# M261_v1 register map
File version: 1.0
Registers are 32-bit, read-write, reset 0x0 unless marked. A register's access mark holds for its fields unless they carry their own. Offsets are from the block's base; [hi:lo] are bit positions; {n}, {i} and the like mark numbered series; 'fields as' and 'values as' point back to an identical list.

## EADC — EADC Register Map
Base 0x40043000
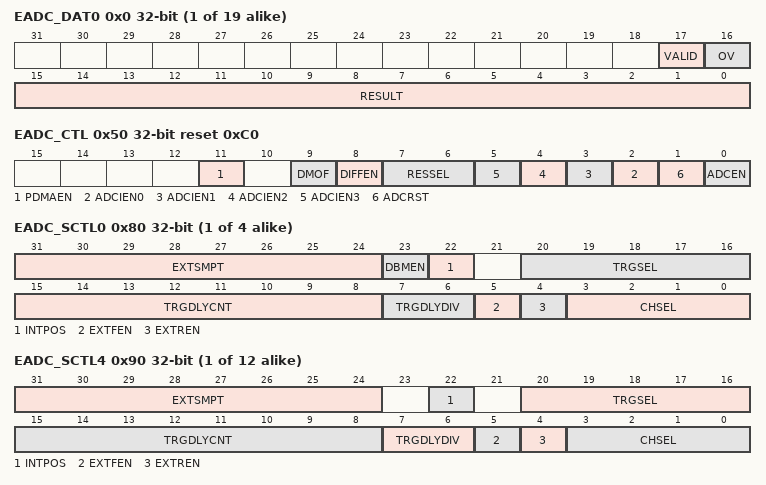
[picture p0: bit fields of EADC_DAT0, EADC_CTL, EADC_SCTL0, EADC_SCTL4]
{0x0+4i} EADC_DAT{i} ro (i=0..18) — ADC Data Register {i} for Sample Module {i}
  [17] VALID — Valid Flag. This bit is set to 1 when corresponding sample module channel analog input conversion is completed and cleared by hardware after EADC_DAT register is read.
    0=Data in RESULT[11:0] bits is not valid; 1=Data in RESULT[11:0] bits is valid
  [16] OV — Overrun Flag. If converted data in RESULT[11:0] has not been read before new conversion result is loaded to this register, OV is set to 1. Note: It is cleared by hardware after EADC_DAT register is read.
    0=Data in RESULT[11:0] is recent conversion result; 1=Data in RESULT[11:0] is overwrite
  [15:0] RESULT — ADC Conversion Result. This field contains 12 bits conversion result. When DMOF (EADC_CTL[9]) is set to 0, 12-bit ADC conversion result with unsigned format will be filled in RESULT[11:0] and zero will be filled in RESULT[15:12]. When DMOF (EADC_CTL[9]) set to 1, 12-bit ADC conversion result with 2'complement format will be filled in RESULT[11:0] and signed bits to will be filled in RESULT[15:12].
0x4C EADC_CURDAT ro — ADC PDMA Current Transfer Data Register
  [17:0] CURDAT — ADC PDMA Current Transfer Data (Read Only)
0x50 EADC_CTL reset 0xC0 — ADC Control Register
  [11] PDMAEN — PDMA Transfer Enable Bit. When ADC conversion is completed, the converted data is loaded into EADC_DATn (n: 0 ~ 18) register, user can enable this bit to generate a PDMA data transfer request.
    0=PDMA data transfer Disabled; 1=PDMA data transfer Enabled
  [9] DMOF — ADC Differential Input Mode Output Format
    0=ADC conversion result will be filled in RESULT (EADC_DATn[15:0], where n= 0 ~18) with unsigned format; 1=ADC conversion result will be filled in RESULT (EADC_DATn[15:0], where n= 0 ~18) with 2'complement format
  [8] DIFFEN — Differential Analog Input Mode Enable Bit
    0=Single-end analog input mode; 1=Differential analog input mode
  [7:6] RESSEL — Resolution Selection
    0=6-bit ADC result will be put at RESULT (EADC_DATn[5:0]); 1=8-bit ADC result will be put at RESULT (EADC_DATn[7:0]); 2=10-bit ADC result will be put at RESULT (EADC_DATn[9:0]); 3=12-bit ADC result will be put at RESULT (EADC_DATn[11:0])
  [n+2] ADCIEN{n} (n=0..3) — Specific Sample Module ADC ADINT{n} Interrupt Enable Bit. The ADC converter generates a conversion end ADIF{n} (EADC_STATUS2[{n}]) upon the end of specific sample module ADC conversion. If ADCIEN{n} bit is set then conversion end interrupt request ADINT{n} is generated.
    0=Specific sample module ADC ADINT{n} interrupt function Disabled; 1=Specific sample module ADC ADINT{n} interrupt function Enabled
  [1] ADCRST — ADC Converter Control Circuits Reset. Note: ADCRST bit remains 1 during ADC reset, when ADC reset end, the ADCRST bit is automatically cleared to 0.
    0=No effect; 1=Cause ADC control circuits reset to initial state, but not change the ADC registers value
  [0] ADCEN — ADC Converter Enable Bit. Note: Before starting ADC conversion function, this bit should be set to 1. Clear it to 0 to disable ADC converter analog circuit power consumption.
    0=Disabled EADC; 1=Enabled EADC
0x54 EADC_SWTRG wo — ADC Sample Module Software Start Register
  [18:0] SWTRG — ADC Sample Module 0~18 Software Force to Start ADC Conversion. Note: After writing this register to start ADC conversion, the EADC_PENDSTS register will show which sample module will conversion. If user want to disable the conversion of the sample module, user can write EADC_PENDSTS register to clear it.
    0=No effect; 1=Cause an ADC conversion when the priority is given to sample module
0x58 EADC_PENDSTS — ADC Start of Conversion Pending Flag Register
  [18:0] STPF — ADC Sample Module 0~18 Start of Conversion Pending Flag. Read Operation:
    0=There is no pending conversion for sample module; 1=Sample module ADC start of conversion is pending. Cear pending flag cancel the conversion for sample module
0x5C EADC_OVSTS — ADC Sample Module Start of Conversion Overrun Flag Register
  [18:0] SPOVF — ADC SAMPLE0~18 Overrun Flag. Note: This bit is cleared by writing 1 to it.
    0=No sample module event overrun; 1=Indicates a new sample module event is generated while an old one event is pending
{0x80+4i} EADC_SCTL{i} (i=0..3) — ADC Sample Module {i} Control Register
  [31:24] EXTSMPT — ADC Sampling Time Extend. When ADC converting at high conversion rate, the sampling time of analog input voltage may not enough if input channel loading is heavy, user can extend ADC sampling time after trigger source is coming to get enough sampling time. The range of start delay time is from 0~255 ADC clock.
  [23] DBMEN — Double Buffer Mode Enable Bit
    0=Sample has one sample result register (default); 1=Sample has two sample result registers
  [22] INTPOS — Interrupt Flag Position Select
    0=Set ADIFn (EADC_STATUS2[n], n=0~3) at ADC end of conversion; 1=Set ADIFn (EADC_STATUS2[n], n=0~3) at ADC start of conversion
  [20:16] TRGSEL — ADC Sample Module Start of Conversion Trigger Source Selection
  [15:8] TRGDLYCNT — ADC Sample Module Start of Conversion Trigger Delay Time
  [7:6] TRGDLYDIV — ADC Sample Module Start of Conversion Trigger Delay Clock Divider Selection. Trigger delay clock frequency:
    0=ADC_CLK/1; 1=ADC_CLK/2; 2=ADC_CLK/4; 3=ADC_CLK/16
  [5] EXTFEN — ADC External Trigger Falling Edge Enable Bit
    0=Falling edge Disabled when ADC selects EADC0_ST as trigger source; 1=Falling edge Enabled when ADC selects EADC0_ST as trigger source
  [4] EXTREN — ADC External Trigger Rising Edge Enable Bit
    0=Rising edge Disabled when ADC selects EADC0_ST as trigger source; 1=Rising edge Enabled when ADC selects EADC0_ST as trigger source
  [3:0] CHSEL — ADC Sample Module Channel Selection
{0x80+4i} EADC_SCTL{i} (i=4..15) — ADC Sample Module {i} Control Register
  [31:24] EXTSMPT — ADC Sampling Time Extend. When ADC converting at high conversion rate, the sampling time of analog input voltage may not enough if input channel loading is heavy, SW can extend ADC sampling time after trigger source is coming to get enough sampling time. The range of start delay time is from 0~255 ADC clock.
  [22] INTPOS — Interrupt Flag Position Select
    values as EADC_SCTL0.INTPOS
  [20:16] TRGSEL — ADC Sample Module Start of Conversion Trigger Source Selection
  [15:8] TRGDLYCNT — ADC Sample Module Start of Conversion Trigger Delay Time
  [7:6] TRGDLYDIV — ADC Sample Module Start of Conversion Trigger Delay Clock Divider Selection. Trigger delay clock frequency:
    0=ADC_CLK/1; 1=ADC_CLK/2; 2=ADC_CLK/4; 3=ADC_CLK/16
  [5] EXTFEN — ADC External Trigger Falling Edge Enable Bit
    values as EADC_SCTL0.EXTFEN
  [4] EXTREN — ADC External Trigger Rising Edge Enable Bit
    values as EADC_SCTL0.EXTREN
  [3:0] CHSEL — ADC Sample Module Channel Selection
{0x80+4i} EADC_SCTL{i} (i=16..18) — ADC Sample Module {i} Control Register
  [31:24] EXTSMPT — ADC Sampling Time Extend. When ADC converting at high conversion rate, the sampling time of analog input voltage may not enough if input channel loading is heavy, SW can extend ADC sampling time after trigger source is coming to get enough sampling time. The range of start delay time is from 0~255 ADC clock.
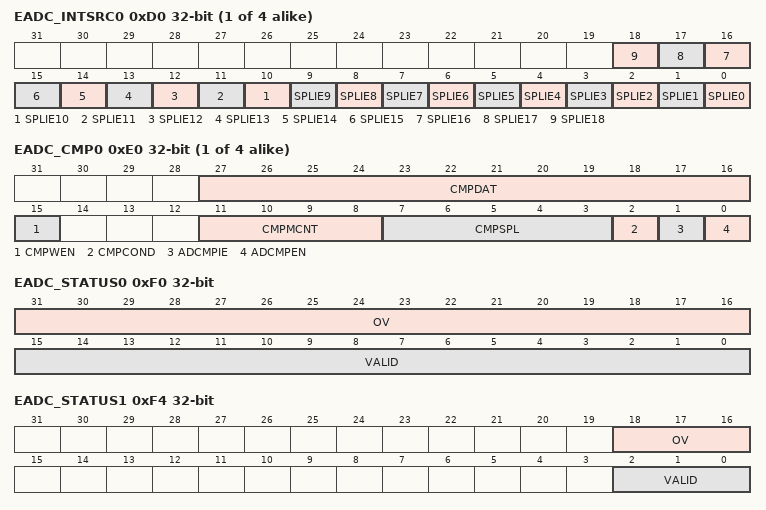
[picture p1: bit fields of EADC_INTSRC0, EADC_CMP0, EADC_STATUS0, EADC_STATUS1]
{0xD0+4i} EADC_INTSRC{i} (i=0..3) — ADC interrupt {i} Source Enable Control Register.
  [n] SPLIE{n} (n=0..18) — Sample Module {n} Interrupt Enable Bit
    0=Sample Module {n} interrupt Disabled; 1=Sample Module {n} interrupt Enabled
{0xE0+4i} EADC_CMP{i} (i=0..3) — ADC Result Compare Register {i}
  [27:16] CMPDAT — Comparison Data. The 12 bits data is used to compare with conversion result of specified sample module. User can use it to monitor the external analog input pin voltage transition without imposing a load on software.
  [15] CMPWEN — Compare Window Mode Enable Bit. Note: This bit is only present in EADC_CMP0 and EADC_CMP2 register.
    0=ADCMPF0 (EADC_STATUS2[4]) will be set when EADC_CMP0 compared condition matched. ADCMPF2 (EADC_STATUS2[6]) will be set when EADC_CMP2 compared condition matched; 1=ADCMPF0 (EADC_STATUS2[4]) will be set when both EADC_CMP0 and EADC_CMP1 compared condition matched. ADCMPF2 (EADC_STATUS2[6]) will be set when both EADC_CMP2 and EADC_CMP3 compared condition matched
  [11:8] CMPMCNT — Compare Match Count
  [7:3] CMPSPL — Compare Sample Module Selection
    {v}=Sample Module {v} conversion result EADC_DAT{v} is selected to be compared (v=0..18)
  [2] CMPCOND — Compare Condition
    0=Set the compare condition as that when a 12-bit ADC conversion result is less than the 12-bit CMPDAT (EADC_CMPn [27:16]), the internal match counter will increase one; 1=Set the compare condition as that when a 12-bit ADC conversion result is greater or equal to the 12-bit CMPDAT (EADC_CMPn [27:16]), the internal match counter will increase one
  [1] ADCMPIE — ADC Result Compare Interrupt Enable Bit
    0=Compare function interrupt Disabled; 1=Compare function interrupt Enabled
  [0] ADCMPEN — ADC Result Compare Enable Bit
    0=Compare Disabled; 1=Compare Enabled
0xF0 EADC_STATUS0 ro — ADC Status Register 0
  [31:16] OV — EADC_DAT0~15 Overrun Flag
  [15:0] VALID — EADC_DAT0~15 Data Valid Flag
0xF4 EADC_STATUS1 ro — ADC Status Register 1
  [18:16] OV — EADC_DAT16~18 Overrun Flag
  [2:0] VALID — EADC_DAT16~18 Data Valid Flag
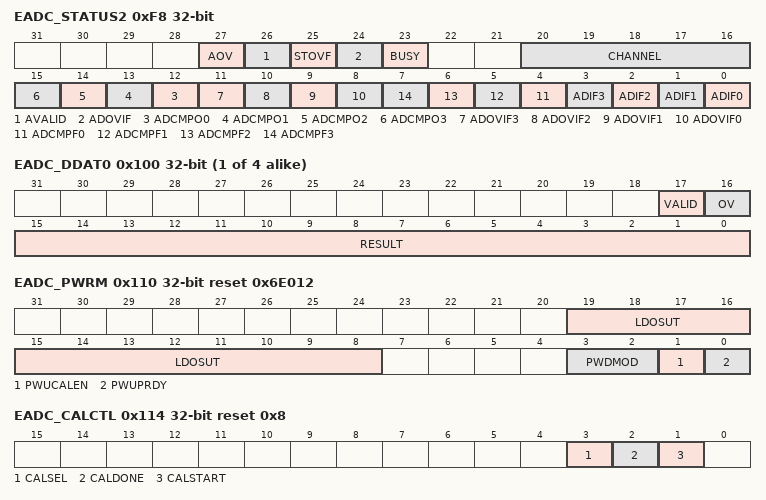
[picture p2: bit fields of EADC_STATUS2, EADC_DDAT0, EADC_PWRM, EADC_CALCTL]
0xF8 EADC_STATUS2 — ADC Status Register 2
  [27] AOV ro — for All Sample Module ADC Result Data Register Overrun Flags Check (Read Only). Note: This bit will keep 1 when any OVn Flag is equal to 1.
    0=None of sample module data register overrun flag OVn (EADC_DATn[16]) is set to 1; 1=Any one of sample module data register overrun flag OVn (EADC_DATn[16]) is set to 1
  [26] AVALID ro — for All Sample Module ADC Result Data Register EADC_DAT Data Valid Flag Check (Read Only). Note: This bit will keep 1 when any VALIDn Flag is equal to 1.
    0=None of sample module data register valid flag VALIDn (EADC_DATn[17]) is set to 1; 1=Any one of sample module data register valid flag VALIDn (EADC_DATn[17]) is set to 1
  [25] STOVF ro — for All ADC Sample Module Start of Conversion Overrun Flags Check (Read Only). Note: This bit will keep 1 when any SPOVFn Flag is equal to 1.
    0=None of sample module event overrun flag SPOVFn (EADC_OVSTS[n]) is set to 1; 1=Any one of sample module event overrun flag SPOVFn (EADC_OVSTS[n]) is set to 1
  [24] ADOVIF ro — All ADC Interrupt Flag Overrun Bits Check (Read Only). Note: This bit will keep 1 when any ADOVIFn Flag is equal to 1.
    0=None of ADINT interrupt flag ADOVIFn (EADC_STATUS2[11:8]) is overwritten to 1; 1=Any one of ADINT interrupt flag ADOVIFn (EADC_STATUS2[11:8]) is overwritten to 1
  [23] BUSY ro — Busy/Idle (Read Only)
    0=EADC is in idle state; 1=EADC is busy at conversion
  [20:16] CHANNEL ro — Current Conversion Channel (Read Only)
  [n+12] ADCMPO{n} ro (n=0..3) — ADC Compare {n} Output Status (Read Only). The 12 bits compare{n} data CMPDAT{n} (EADC_CMP{n}[27:16]) is used to compare with conversion result of specified sample module. User can use it to monitor the external analog input pin voltage status.
    0=Conversion result in EADC_DAT less than CMPDAT{n} setting; 1=Conversion result in EADC_DAT great than or equal CMPDAT{n} setting
  [11] ADOVIF3 — ADC ADINT3 Interrupt Flag Overrun. Note: This bit is cleared by writing 1 to it.
    0=ADINT3 interrupt flag is not overwritten to 1; 1=ADINT3 interrupt flag is overwritten to 1
  [10] ADOVIF2 — ADC ADINT2 Interrupt Flag Overrun. Note: This bit is cleared by writing 1 to it.
    0=ADINT2 interrupt flag is not overwritten to 1; 1=ADINT2 interrupt flag is s overwritten to 1
  [9] ADOVIF1 — ADC ADINT1 Interrupt Flag Overrun. Note: This bit is cleared by writing 1 to it.
    0=ADINT1 interrupt flag is not overwritten to 1; 1=ADINT1 interrupt flag is overwritten to 1
  [8] ADOVIF0 — ADC ADINT0 Interrupt Flag Overrun. Note: This bit is cleared by writing 1 to it.
    0=ADINT0 interrupt flag is not overwritten to 1; 1=ADINT0 interrupt flag is overwritten to 1
  [n+4] ADCMPF{n} (n=0..3) — ADC Compare {n} Flag. When the specific sample module ADC conversion result meets setting condition in EADC_CMP{n} then this bit is set to 1. Note: This bit is cleared by writing 1 to it.
    0=Conversion result in EADC_DAT does not meet EADC_CMP{n} register setting; 1=Conversion result in EADC_DAT meets EADC_CMP{n} register setting
  [n] ADIF{n} (n=0..3) — ADC ADINT{n} Interrupt Flag. Note1: This bit is cleared by writing 1 to it. Note2:This bit indicates whether an ADC conversion of specific sample module has been completed
    0=No ADINT{n} interrupt pulse received; 1=ADINT{n} interrupt pulse has been received
0xFC EADC_STATUS3 ro reset 0x1F — ADC Status Register 3
  [4:0] CURSPL — ADC Current Sample Module (Read Only). This register shows the current ADC is controlled by which sample module control logic modules. If the ADC is Idle, the bit filed will set to 0x1F.
{0x100+4i} EADC_DDAT{i} ro (i=0..3) — ADC Double Data Register {i} for Sample Module {i}
  [17] VALID — Valid Flag
    0=Double data in RESULT (EADC_DDATn[15:0]) is not valid; 1=Double data in RESULT (EADC_DDATn[15:0]) is valid
  [16] OV — Overrun Flag. If converted data in RESULT[15:0] has not been read before new conversion result is loaded to this register, OV is set to 1. It is cleared by hardware after EADC_DDAT register is read.
    0=Data in RESULT (EADC_DATn[15:0], n=0~3) is recent conversion result; 1=Data in RESULT (EADC_DATn[15:0], n=0~3) is overwrite
  [15:0] RESULT — ADC Conversion Results. This field contains 12 bits conversion results. When the DMOF (EADC_CTL[9]) is set to 0, 12-bit ADC conversion result with unsigned format will be filled in RESULT [11:0] and zero will be filled in RESULT [15:12]. When DMOF (EADC_CTL[9]) is set to 1, 12-bit ADC conversion result with 2'complement format will be filled in RESULT [11:0] and signed bits to will be filled in RESULT [15:12].
0x110 EADC_PWRM reset 0x6E012 — ADC Power Management Register
  [19:8] LDOSUT — ADC Internal LDO Start-up Time
  [3:2] PWDMOD — ADC Power-down Mode. Set this bit field to select ADC Power-down mode when system power-down. Note: Different PWDMOD has different power down/up sequence, in order to avoid ADC powering up with wrong sequence; user must keep PWMOD consistent each time in power down and start up.
    0=ADC Deep Power-down mode; 1=ADC Power down; 2=ADC Standby mode; 3=ADC Deep Power-down mode
  [1] PWUCALEN — Power Up Calibration Function Enable Bit. Note: This bit work together with CALSEL (EADC_CALCTL [3]), see the following {PWUCALEN, CALSEL } Description: PWUCALEN is 0 and CALSEL is 0: No need to calibrate. PWUCALEN is 0 and CALSEL is 1: No need to calibrate. PWUCALEN is 1 and CALSEL is 0: Load calibration word when power up. PWUCALEN is 1 and CALSEL is 1: Calibrate when power up.
    0=Calibration function Disabled at power up; 1=Calibration function Enabled at power up
  [0] PWUPRDY ro — ADC Power-up Sequence Completed and Ready for Conversion (Read Only)
    0=ADC is not ready for conversion may be in power down state or in the progress of start up; 1=ADC is ready for conversion
0x114 EADC_CALCTL reset 0x8 — ADC Calibration Control Register
  [3] CALSEL — Select Calibration Functional Block
    0=Load calibration word when calibration functional block is active; 1=Execute calibration when calibration functional block is active
  [2] CALDONE ro — Calibration Functional Block Complete (Read Only)
    0=During a calibration; 1=Calibration is completed
  [1] CALSTART — Calibration Functional Block Start. Note: This bit is set by SW and clear by HW after re-calibration finish
    0=Stop calibration functional block; 1=Start calibration functional block
0x118 EADC_CALDWRD (reset mask 0xFFFFFF00) — ADC Calibration Load Word Register
  [6:0] CALWORD — Calibration Word Bits. Write to this register with the previous calibration word before load calibration action. Read this register after calibration done. Note: The calibration block contains two parts 'CALIBRATION' and 'LOAD CALIBRATION'; if the calibration block configure as 'CALIBRATION'; then this register represent the result of calibration when calibration is completed; if configure as 'LOAD CALIBRATION' ; configure this register before loading calibration action, after loading calibration complete, the laoded calibration word will apply to the ADC; while in loading calibration function the loaded value will not be equal to the original CALWORD until calibration is done.
